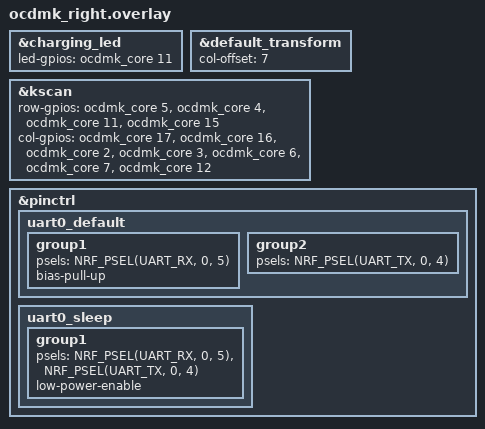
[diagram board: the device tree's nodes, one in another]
/*
 * OCDMK Right Shield Overlay
 */

#include "ocdmk.dtsi"

/* Charging LED output for right side (mirrored: Pin 1 → Pin 11) */
&charging_led {
    led-gpios = <&ocdmk_core 11 GPIO_ACTIVE_HIGH>;  /* Pin 11: P0.11 */
};

&default_transform {
    col-offset = <7>;
};

&kscan {
    /*
     * Row pins (right side - mirrored pinout)
     * Left Pin 5 → Right Pin 15, Left Pin 4 → Right Pin 14, etc.
     * Rows are OUTPUTS (driven high) for row2col diode direction
     */
    row-gpios
        = <&ocdmk_core 5 GPIO_ACTIVE_HIGH>   /* R1: P0.10 */
        , <&ocdmk_core 4 GPIO_ACTIVE_HIGH>   /* R2: P0.09 */
        , <&ocdmk_core 11 GPIO_ACTIVE_HIGH>  /* R3: P0.11 */
        , <&ocdmk_core 15 GPIO_ACTIVE_HIGH>  /* R4: P0.01 */
        ;

    /*
     * Column pins (right side - mirrored)
     * Left Pin 17 → Right Pin 7, Left Pin 2 → Right Pin 12, etc.
     * Columns are INPUTS (with pull-down) for row2col diode direction
     */
    col-gpios
        = <&ocdmk_core 17 (GPIO_ACTIVE_HIGH | GPIO_PULL_DOWN)>  /* C1: P0.29 */
        , <&ocdmk_core 16 (GPIO_ACTIVE_HIGH | GPIO_PULL_DOWN)>  /* C2: P0.28 */
        , <&ocdmk_core 2 (GPIO_ACTIVE_HIGH | GPIO_PULL_DOWN)>   /* C3: P0.17 */
        , <&ocdmk_core 3 (GPIO_ACTIVE_HIGH | GPIO_PULL_DOWN)>   /* C4: P0.20 */
        , <&ocdmk_core 6 (GPIO_ACTIVE_HIGH | GPIO_PULL_DOWN)>   /* C5: P0.03 */
        , <&ocdmk_core 7 (GPIO_ACTIVE_HIGH | GPIO_PULL_DOWN)>   /* C6: P0.02 */
        , <&ocdmk_core 12 (GPIO_ACTIVE_HIGH | GPIO_PULL_DOWN)>  /* C7: P1.09 */
        ;
};

/*
 * UART wired split — right (peripheral): connector pins 14 / 13 → P0.04 (TX) / P0.05 (RX)
 * Crossover to left: Right TX (pin 14) → Left RX (pin 4); Right RX (pin 13) → Left TX (pin 3)
 */
&pinctrl {
    uart0_default: uart0_default {
        group1 {
            psels = <NRF_PSEL(UART_RX, 0, 5)>;
            bias-pull-up;
        };
        group2 {
            psels = <NRF_PSEL(UART_TX, 0, 4)>;
        };
    };
    uart0_sleep: uart0_sleep {
        group1 {
            psels = <NRF_PSEL(UART_RX, 0, 5)>,
                    <NRF_PSEL(UART_TX, 0, 4)>;
            low-power-enable;
        };
    };
};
